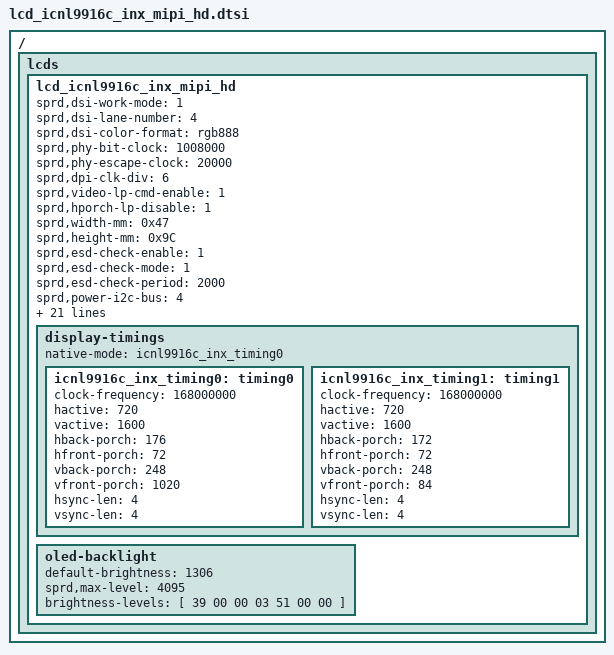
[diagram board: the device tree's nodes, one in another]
/*
 * R61350 Truly LCD config dtsi file for spreadtrum
 *
 * Copyright (C) 2018, Spreadtrum Communications Inc.
 *
 * SPDX-License-Identifier: (GPL-2.0+ OR MIT)
 */

/ {
	fragment {
		target-path = "/";
		__overlay__ {
			lcds {
				lcd_icnl9916c_inx_mipi_hd: lcd_icnl9916c_inx_mipi_hd {

					sprd,dsi-work-mode = <1>; /* video burst mode*/
					sprd,dsi-lane-number = <4>;
					sprd,dsi-color-format = "rgb888";

					sprd,phy-bit-clock = <1008000>;	/* kbps */
					sprd,phy-escape-clock = <20000>;/* kHz */
					sprd,dpi-clk-div = <6>;
					sprd,video-lp-cmd-enable = <1>;
					sprd,hporch-lp-disable = <1>;

					sprd,width-mm = <0x47>;
					sprd,height-mm = <0x9C>;

					sprd,esd-check-enable = <1>;
					sprd,esd-check-mode = <1>;
					sprd,esd-check-period = <2000>;
					//sprd,esd-check-register = <0x0A>;
					//sprd,esd-check-value = <0x9C>;

					sprd,power-i2c-bus = <4>;
					sprd,power-i2c-addr = <0x3e>;
					sprd,power-i2c-reg = [00 01 03];
					sprd,power-i2c-val = [14 14 43];

					sprd,reset-on-sequence = <1 15>, <0 5>, <1 30>;
					sprd,reset-off-sequence = <1 5>;
					/*
					 * Use 4 bits number for descripting video lp mode, and it can be combined used.
					 * BIT(0): allow vactive enter lp;
					 * BIT(1): allow vfp enter lp;
					 * BIT(2): allow vbp enter lp;
					 * BIT(3): allow vsa enter lp;
					 * For example:
					 * If we need vfp & vbp enter lp, we can calculate this value as a result of BIT(1) | BIT(2)
					 * And we get the result of 3 and set this value to lcd dt property sprd,video-lp-en-mode.
					 * If we need all stage can enter lp, we can calculate this value as a result of BIT(0) | BIT(1) | BIT(2) | BIT(3).
					 * And we get the result of 15 and set this value to lcd dt property sprd,video-lp-en-mode.
					 */
					sprd,video-lp-en-mode = <2>;
					sprd,use-dcs-write;
					sprd,initial-command = [
						39 00 00 04 F0 99 16 0C
						39 00 00 15 C0 40 93 FF FF FF 3F FF 00 FF 00 CC B1 23 45 67 89 AD FF FF F0 //BISTMODE
						39 00 00 21 C1 00 F8 20 54 04 AC 48 04 40 06 22 70 30 30 07 11 84 4C 00 93 13 63 00 00 00 00 00 00 00 00 00 00
						39 00 00 06 C2 11 05 01 10 80
						39 00 00 09 C3 06 00 FF 00 FF 5C 10 01
						39 00 00 0D C4 04 31 B8 40 00 BC 00 00 00 00 00 F0
						39 00 00 18 C5 03 21 96 C8 3E 00 09 01 14 04 0F 18 C6 03 64 FF 01 04 18 22 45 14 38
						39 00 00 0D C6 72 24 13 2B 2B 28 3F 02 16 96 00 01
						15 00 00 02 CA 00
						39 00 00 19 B2 70 11 09 10 96 36 0B 07 44 10 10 10 10 10 10 10 10 52 6E 52 6E 00 00 00
						39 00 00 0C B3 B4 07 02 0F 81 65 00 00 64 08 00
						39 00 00 16 B4 00 10 15 10 15 26 26 91 A2 33 44 00 26 00 55 3C 02 08 20 30 00
						39 00 00 21 B5 00 00 32 32 00 00 33 00 00 00 33 0D 0F 11 13 15 17 09 07 05 00 00 FF FF FC 32 20 00 00 00 00 00
						39 00 00 21 B6 00 00 32 32 00 00 33 00 00 00 33 0C 0E 10 12 14 16 08 06 04 00 00 FF FF FC 32 20 00 00 00 00 00
						39 00 00 17 B7 5A 5A 5A 5A 5A 5A 5A 5A 5A 5A 5A 5A 5A 5A 5A 5A 5A 5A 5A 5A 5A 5A
						39 00 00 09 BB 01 02 03 0A 04 13 14 00
						39 00 00 14 BC 00 00 00 00 04 00 FF F0 0B 33 54 5B 33 33 00 5A 46 52 3E //VGHO14/VGLO-12/VGH14.8/VGL-12.8
						39 00 00 1F CA 25 40 04 19 46 94 41 8F 22 33 52 64 3E 34 5A 6E 46 3C 11 00 01 01 08 01 06 00 05 00 00 04
						39 00 00 0E BD A1 0A 52 AE 8F 04 C7 C1 06 03 2E 15 01
						39 00 00 0A BF 0C 19 0C 19 00 11 04 18 50
						39 00 00 1C C7 76 54 32 22 34 56 77 77 30 76 54 32 22 34 56 77 77 10 31 00 01 FF FF 00 82 91 40
						39 00 00 21 80 FF FB F4 ED E8 E4 E0 DC D8 CD C4 BC B6 B0 A9 9E 94 8A 7E 7D 72 68 5D 50 40 2E 29 1A 16 13 0E 0B
						39 00 00 21 81 FF FB F4 ED E8 E4 E0 DC D8 CD C4 BC B6 B0 A9 9E 94 8A 7E 7D 72 68 5D 50 40 2E 29 1A 16 13 0E 0B
						39 00 00 21 82 FF FB F4 ED E8 E4 E0 DC D8 CD C4 BC B6 B0 A9 9E 94 8A 7E 7D 72 68 5D 50 40 2E 29 1A 16 13 0E 0B
						39 00 00 1A 83 03 08 05 02 02 08 05 02 02 08 05 02 02 06 03 01 00 06 03 01 01 06 03 01 01
						39 00 00 1C 84 11 D2 E2 59 2E 44 24 CD EE 11 D2 E2 59 2E 44 24 CD EE 11 D2 E2 59 2E 44 24 CD EE
						39 00 00 21 85 FB F7 EF E8 E4 DF DB D7 D4 C8 BF B7 B0 A9 A2 97 8B 80 74 73 67 5D 52 44 37 2B 1B 10 0F 0D 0B 08
						39 00 00 21 86 FB F7 EF E8 E4 DF DB D7 D4 C8 BF B7 B0 A9 A2 97 8B 80 74 73 67 5D 52 44 37 2B 1B 10 0F 0D 0B 08
						39 00 00 21 87 FB F7 EF E8 E4 DF DB D7 D4 C8 BF B7 B0 A9 A2 97 8B 80 74 73 67 5D 52 44 37 2B 1B 10 0F 0D 0B 08
						39 00 00 1C 8B 1F 7B 21 E8 55 D7 67 06 64 1F 7B 21 E8 55 D7 67 06 64 1F 7B 21 E8 55 D7 67 06 64

						39 00 00 05 C8 46 00 88 98
						39 00 00 21 E0 0C 00 B0 10 00 07 B7 29 00 21 02 00 00 00 00 24 12 08 11 48 47 00 00 FF 00 00 00 00 00 00 00 00
						39 00 00 05 BD A1 0A 52 A6
						39 00 00 03 35 00 00
						39 00 00 03 51 00 00
						39 00 00 03 53 24 00
						39 00 00 03 55 00 00
						39 78 00 03 11 00 00
						39 0A 00 03 29 00 00
						39 00 00 03 6D 02 00
						39 00 00 05 BD A1 0A 52 AE
						39 05 00 04 F0 00 00 00
						];

					sprd,sleep-in-command = [
						39 00 00 03 6D 25 00
						39 14 00 03 28 00 00
						39 78 00 03 10 00 00
						];

					sprd,sleep-out-command = [
						05 14 00 01 11
						05 78 00 01 29
						];

					sprd,cabc-off-command = [
						39 00 00 03 55 00 00
						];
					sprd,cabc-ui-command = [
						39 00 00 04 F0 99 16 0C
						39 00 00 03 55 01 00
						39 00 00 20 E1 0F 1F 2F 3F 4F 5F 6F 7F 90 A0 B0 C0 D0 E0 EA F6 F6 F6 F6 F6 F2 F7 F7 F5 F6 F6 F3 F4 F6 F6 FF
						39 00 00 21 E2 32 F8 39 6B 39 6B 39 6B 3B 80 3B 80 39 6B 39 6F 39 6B 39 6B 39 6B 38 51 39 6B 39 6B 39 6B 3E 70
						39 00 00 04 F0 00 00 00
						];
					sprd,cabc-still-command = [
						39 00 00 04 F0 99 16 0C
						39 00 00 03 55 02 00
						39 00 00 20 E1 0F 1F 2F 3F 4F 5F 6F 7F 90 99 B7 C0 D0 E0 F2 D0 D0 D0 DD E1 DF E1 E1 E0 E0 E3 EB E3 E3 E3 E3
						39 00 00 21 E2 26 F8 2D 00 2D 00 2D 00 2E 80 2D 00 2D 00 2D 00 2D 00 2D 00 2D D0 2E 80 2D 00 32 00 36 00 39 70
						39 00 00 04 F0 00 00 00
						];
					sprd,cabc-moving-command = [
						39 00 00 03 55 00 00
						];

					display-timings {
						native-mode = <&icnl9916c_inx_timing0>;

						icnl9916c_inx_timing0: timing0 {
							clock-frequency = <168000000>;
							hactive = <720>;
							vactive = <1600>;
							hback-porch = <176>;
							hfront-porch = <72>;
							vback-porch = <248>;
							vfront-porch = <1020>;
							hsync-len = <4>;
							vsync-len = <4>;
						};
						icnl9916c_inx_timing1: timing1 {
							clock-frequency = <168000000>;
							hactive = <720>;
							vactive = <1600>;
							hback-porch = <172>;
							hfront-porch = <72>;
							vback-porch = <248>;
							vfront-porch = <84>;
							hsync-len = <4>;
							vsync-len = <4>;
						};
					};
					oled-backlight {
						default-brightness = <1306>;
						sprd,max-level = <4095>;
						brightness-levels = [
							39 00 00 03 51 00 00
						];
					};
				};
			};
		};
	};
};
